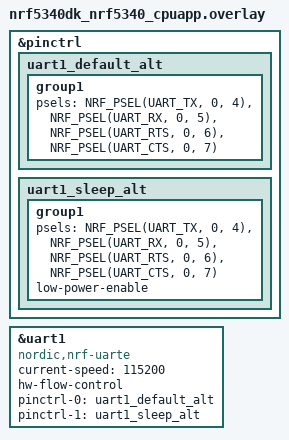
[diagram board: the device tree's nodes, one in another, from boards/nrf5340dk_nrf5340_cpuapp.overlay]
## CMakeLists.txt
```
# Copyright (c) 2023 Trackunit Corporation
# SPDX-License-Identifier: Apache-2.0

cmake_minimum_required(VERSION 3.28.0)
find_package(Zephyr REQUIRED HINTS $ENV{ZEPHYR_BASE})
project(modem_backend_uart_test)

target_sources(app PRIVATE src/main.c)
```

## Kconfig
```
# Copyright (c) 2025 Nordic Semiconductor ASA
# SPDX-License-Identifier: Apache-2.0

source "Kconfig.zephyr"

config TEST_HW_FLOW_CONTROL
	bool "Test hardware flow control"
	help
	  By default, the test uses backend transmit and receive
	  buffers of adequate size, and waits until transmitted
	  data has been fully received before next transmit.

	  This option limits the backend receive buffer size and
	  imposes a delay on reading received data, ensuring
	  transmitted data will be dropped if hw flow control is
	  not enabled.
```

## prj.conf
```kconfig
# Copyright (c) 2023 Trackunit Corporation
# SPDX-License-Identifier: Apache-2.0

CONFIG_MODEM_MODULES=y
CONFIG_MODEM_BACKEND_UART=y
CONFIG_SERIAL=y
CONFIG_ZTEST=y
CONFIG_LOG=y
CONFIG_ZTEST_SHUFFLE=y
CONFIG_ZTEST_REPEAT=y
CONFIG_ZTEST_TEST_REPEAT_COUNT=3
```

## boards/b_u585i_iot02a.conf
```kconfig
# SPDX-FileCopyrightText: Copyright The Zephyr Project Contributors
# SPDX-License-Identifier: Apache-2.0

CONFIG_GPIO=y
```

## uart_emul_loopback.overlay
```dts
/* SPDX-License-Identifier: Apache-2.0 */

/ {
	dut: uart-emul {
		compatible = "zephyr,uart-emul";
		status = "okay";
		loopback;

		/*
		 * Hold enough incoming data to exercise the backend's
		 * receive-buffer-full path while RX processing is delayed.
		 */
		rx-fifo-size = <4096>;

		/* Accommodate the test's 8192-byte transmission. */
		tx-fifo-size = <8192>;
	};
};
```

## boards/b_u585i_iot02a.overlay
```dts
/* SPDX-License-Identifier: Apache-2.0 */

/*
 * The following bridges must be applied:
 *
 *   CN2 pin 2 <-> CN2 pin 3
 *   CN2 pin 1 <-> CN2 pin 4
 *
 */

&gpioh {
	status = "okay";

	stmod_alternate_uart {
		gpio-hog;
		gpios = <15 GPIO_ACTIVE_HIGH>;
		output-high;
	};
};

dut: &usart3 {
	pinctrl-0 = <&usart3_tx_pd8
		     &usart3_rx_pd9
		     &usart3_rts_pd12
		     &usart3_cts_pd11>;
	pinctrl-names = "default";
	dmas = <&gpdma1 29 STM32_DMA_PERIPH_TX>,
	       <&gpdma1 28 STM32_DMA_PERIPH_RX>;
	dma-names = "tx", "rx";
	hw-flow-control;
};
```

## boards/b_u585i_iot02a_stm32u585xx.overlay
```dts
/* SPDX-License-Identifier: Apache-2.0 */

/*
 * The Arduino D0 and D1 must be connected to each other to loopback RX/TX.
 */

dut: &usart3 {
	dmas = <&gpdma1 0 29 STM32_DMA_PERIPH_TX
		&gpdma1 1 28 STM32_DMA_PERIPH_RX>;
	dma-names = "tx", "rx";
};
```

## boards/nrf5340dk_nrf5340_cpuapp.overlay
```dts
/* SPDX-License-Identifier: Apache-2.0 */

/*
 * Pins P0.4 and P0.5 must be connected to each other to loopback RX/TX.
 * Pins P0.6 and P0.7 must be connected to each other to loopback RTC/CTS.
 */

&pinctrl {
	uart1_default_alt: uart1_default_alt {
		group1 {
			psels = <NRF_PSEL(UART_TX, 0, 4)>,
				<NRF_PSEL(UART_RX, 0, 5)>,
				<NRF_PSEL(UART_RTS, 0, 6)>,
				<NRF_PSEL(UART_CTS, 0, 7)>;
		};
	};

	uart1_sleep_alt: uart1_sleep_alt {
		group1 {
			psels = <NRF_PSEL(UART_TX, 0, 4)>,
				<NRF_PSEL(UART_RX, 0, 5)>,
				<NRF_PSEL(UART_RTS, 0, 6)>,
				<NRF_PSEL(UART_CTS, 0, 7)>;
			low-power-enable;
		};
	};
};

dut: &uart1 {
	compatible = "nordic,nrf-uarte";
	current-speed = <115200>;
	hw-flow-control;
	pinctrl-0 = <&uart1_default_alt>;
	pinctrl-1 = <&uart1_sleep_alt>;
	pinctrl-names = "default", "sleep";
	status = "okay";
};
```

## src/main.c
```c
/*
 * Copyright (c) 2023 Trackunit Corporation
 *
 * SPDX-License-Identifier: Apache-2.0
 */

/*
 * This test suite sets up a modem_backend_uart instance connected to a UART which has its
 * RX and TX pins wired together to provide loopback functionality. A large number of bytes
 * containing a sequence of pseudo random numbers are then transmitted, received, and validated.
 *
 * The test suite repeats three times, opening and closing the modem_pipe attached to the
 * modem_backend_uart instance before and after the tests respectively.
 */

/*************************************************************************************************/
/*                                        Dependencies                                           */
/*************************************************************************************************/
#include <zephyr/ztest.h>
#include <zephyr/kernel.h>
#include <zephyr/sys/atomic.h>
#include <zephyr/modem/backend/uart.h>

#include <stdio.h>
#include <stdlib.h>
#include <string.h>

#ifdef CONFIG_TEST_HW_FLOW_CONTROL
#define TEST_BACKEND_RECEIVE_BUFFER_SIZE 256
#else
#define TEST_BACKEND_RECEIVE_BUFFER_SIZE 4096
#endif

/*************************************************************************************************/
/*                                          Mock pipe                                            */
/*************************************************************************************************/
static const struct device *uart = DEVICE_DT_GET(DT_NODELABEL(dut));
static struct modem_backend_uart uart_backend;
static struct modem_pipe *pipe;
K_SEM_DEFINE(receive_ready_sem, 0, 1);

/*************************************************************************************************/
/*                                          Buffers                                              */
/*************************************************************************************************/
static uint8_t backend_receive_buffer[TEST_BACKEND_RECEIVE_BUFFER_SIZE];
static uint8_t backend_transmit_buffer[4096];
RING_BUF_DECLARE(transmit_ring_buf, 4096);
static uint8_t receive_buffer[4096];

/*************************************************************************************************/
/*                                     Modem pipe callback                                       */
/*************************************************************************************************/
static void modem_pipe_callback_handler(struct modem_pipe *pipe, enum modem_pipe_event event,
					void *user_data)
{
	switch (event) {
	case MODEM_PIPE_EVENT_RECEIVE_READY:
		k_sem_give(&receive_ready_sem);
		break;
	default:
		break;
	}
}

/*************************************************************************************************/
/*                                          Helpers                                              */
/*************************************************************************************************/
static uint32_t transmit_prng_state = 1234;
static uint32_t receive_prng_state = 1234;
static uint32_t transmit_size_prng_state;

static uint8_t transmit_prng_random(void)
{
	transmit_prng_state = ((1103515245 * transmit_prng_state) + 12345) % (1U << 31);
	return (uint8_t)(transmit_prng_state & 0xFF);
}

static uint8_t receive_prng_random(void)
{
	receive_prng_state = ((1103515245 * receive_prng_state) + 12345) % (1U << 31);
	return (uint8_t)(receive_prng_state & 0xFF);
}

static void prng_reset(void)
{
	transmit_prng_state = 1234;
	receive_prng_state = 1234;
	transmit_size_prng_state = 0;
}

static void fill_transmit_ring_buf(void)
{
	uint32_t space = ring_buf_space_get(&transmit_ring_buf);
	uint8_t data;

	for (uint32_t i = 0; i < space; i++) {
		data = transmit_prng_random();
		ring_buf_put(&transmit_ring_buf, &data, 1);
	}
}

static uint32_t transmit_size_prng_random(void)
{
	uint32_t size = 1;

	for (uint8_t i = 0; i < transmit_size_prng_state; i++) {
		size = size * 2;
	}

	transmit_size_prng_state = transmit_size_prng_state == 11
				 ? 0
				 : transmit_size_prng_state + 1;

	return size;
}

static int transmit_prng(uint32_t remaining)
{
	uint8_t *reserved;
	uint32_t reserved_size;
	uint32_t transmit_size;
	int ret;

	fill_transmit_ring_buf();
	reserved_size = ring_buf_get_ptr(&transmit_ring_buf, &reserved, 0);
	transmit_size = MIN(transmit_size_prng_random(), reserved_size);
	transmit_size = MIN(remaining, transmit_size);
	ret = modem_pipe_transmit(pipe, reserved, transmit_size);
	if (ret < 0) {
		return ret;
	}
	printk("TX: %u,%u\n", transmit_size, (uint32_t)ret);
	__ASSERT(ret <= remaining, "Impossible number of bytes sent %u", (uint32_t)ret);
	ring_buf_consume(&transmit_ring_buf, ret);
	return ret;
}

static int receive_prng(void)
{
	int ret;

	if (k_sem_take(&receive_ready_sem, K_SECONDS(1))) {
		return -ETIMEDOUT;
	}

	if (IS_ENABLED(CONFIG_TEST_HW_FLOW_CONTROL)) {
		k_msleep(100);
	}

	ret = modem_pipe_receive(pipe, receive_buffer, sizeof(receive_buffer));
	if (ret == 0) {
		return -ENODATA;
	}

	if (ret < 0) {
		return -EFAULT;
	}

	for (uint32_t i = 0; i < (uint32_t)ret; i++) {
		if (receive_prng_random() != receive_buffer[i]) {
			return -EFAULT;
		}
	}

	printk("RX: %u\n", (uint32_t)ret);
	return ret;
}

/*************************************************************************************************/
/*                                         Test setup                                            */
/*************************************************************************************************/
static void *test_modem_backend_uart_setup(void)
{
	const struct modem_backend_uart_config config = {
		.uart = uart,
		.receive_buf = backend_receive_buffer,
		.receive_buf_size = sizeof(backend_receive_buffer),
		.transmit_buf = backend_transmit_buffer,
		.transmit_buf_size = sizeof(backend_transmit_buffer),
	};

	pipe = modem_backend_uart_init(&uart_backend, &config);
	modem_pipe_attach(pipe, modem_pipe_callback_handler, NULL);
	return NULL;
}

static void test_modem_backend_uart_before(void *f)
{
	prng_reset();
	ring_buf_reset(&transmit_ring_buf);
	k_sem_reset(&receive_ready_sem);
	__ASSERT_NO_MSG(modem_pipe_open(pipe, K_SECONDS(1)) == 0);
}

static void test_modem_backend_uart_after(void *f)
{
	__ASSERT_NO_MSG(modem_pipe_close(pipe, K_SECONDS(1)) == 0);
}

/*************************************************************************************************/
/*                                             Tests                                             */
/*************************************************************************************************/
ZTEST(modem_backend_uart_suite, test_transmit_receive)
{
	int32_t remaining = 8192;
	uint32_t received = 0;
	uint32_t transmitted = 0;
	int ret;

	while ((remaining != 0) || (received < 8192)) {
		ret = transmit_prng(remaining);
		zassert(ret > -1, "Failed to transmit data");
		remaining -= (uint32_t)ret;
		transmitted += (uint32_t)ret;
		printk("TX ACC: %u\n", transmitted);

		while (received < transmitted) {
			ret = receive_prng();
			zassert(ret > -1, "Received data is corrupted");
			received += (uint32_t)ret;
		}
	}
}

ZTEST(modem_backend_uart_suite, test_close_open)
{
	zassert_ok(modem_pipe_close(pipe, K_SECONDS(1)));
	zassert_ok(modem_pipe_open(pipe, K_SECONDS(1)));
	zassert_ok(modem_pipe_close(pipe, K_SECONDS(1)));
	zassert_ok(modem_pipe_open(pipe, K_SECONDS(1)));
	zassert_ok(modem_pipe_close(pipe, K_SECONDS(1)));
	zassert_ok(modem_pipe_open(pipe, K_SECONDS(1)));
	zassert_ok(modem_pipe_close(pipe, K_SECONDS(1)));
	zassert_ok(modem_pipe_open(pipe, K_SECONDS(1)));
}

ZTEST_SUITE(modem_backend_uart_suite, NULL, test_modem_backend_uart_setup,
	    test_modem_backend_uart_before, test_modem_backend_uart_after, NULL);
```
